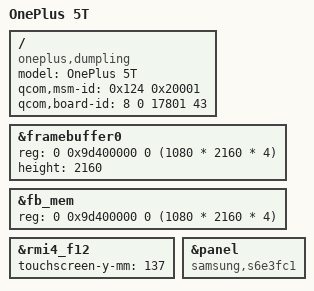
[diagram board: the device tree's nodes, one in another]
// SPDX-License-Identifier: GPL-2.0-only
/*
 * OnePlus 5T (dumpling) device tree
 *
 * Copyright (c) 2021, The Linux Foundation. All rights reserved.
 */

#include "msm8998-oneplus-common.dtsi"

/ {
	model = "OnePlus 5T";
	compatible = "oneplus,dumpling", "qcom,msm8998";
	/* Required for bootloader to select correct board */
	qcom,msm-id = <0x124 0x20001>; /* 8998 v2.1 */
	qcom,board-id = <8 0 17801 43>; // 53, 43?
	// FIXME: Regardless of above, appending both model DTBs doesn't boot on 5T!
};

/* Update the screen height values from 1920 to 2160 on the 5T */
&framebuffer0 {
	reg = <0 0x9d400000 0 (1080 * 2160 * 4)>;
	height = <2160>;
};

&fb_mem {
	reg = <0 0x9d400000 0 (1080 * 2160 * 4)>;
};

/* Adjust digitizer area height to match the 5T's taller panel */
&rmi4_f12 {
	touchscreen-y-mm = <137>;
};

/* Display */
&panel {
	compatible = "samsung,s6e3fc1";
};
